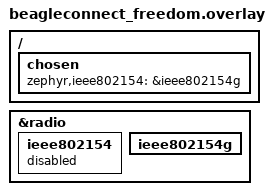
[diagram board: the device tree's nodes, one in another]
/* beagleconnect_freedom.overlay */

/ {
    chosen {
        zephyr,ieee802154     = &ieee802154g;
    };
};

&radio {
    status = "okay";
    ieee802154 {
        status = "disabled";
    };

    ieee802154g {
        status = "okay";
    };
};

